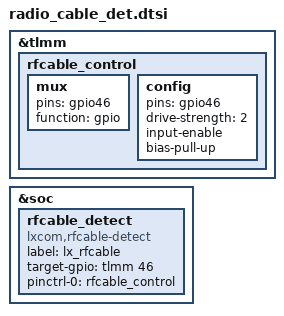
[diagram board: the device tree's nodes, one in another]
&tlmm {
	rfcable_control: rfcable_control {
		mux {
			pins = "gpio46";
			function = "gpio";
		};
		config {
			pins = "gpio46";
			drive-strength = <2>;
			input-enable;
			bias-pull-up;
		};
	};
};

&soc {
	rfcable_detect {
		compatible = "lxcom,rfcable-detect";
		label = "lx_rfcable";
		target-gpio = <&tlmm 46 GPIO_ACTIVE_HIGH>;
		pinctrl-names = "rf_luxcable_det";
		pinctrl-0 = <&rfcable_control>;
	};
};
